VERSION "(null)"

NS_ :

BS_:

BU_:
VAL_TABLE_ Img 6 "Description for the value '0x6'" 5 "Description for the value '0x5'" 4 "Description for the value '0x4'" 3 "Description for the value '0x3'" 2 "Bertone" 1 "GB110" 0 "Car Parameter" ;

BO_ 16 Schermata: 1 Vector__XXX
 SG_ Setup : 0|8@1+ (1,0) [0|255] "" Vector__XXX

BO_ 290 battery: 2 Vector__XXX
 SG_ voltage : 8|8@1+ (1,0) [0|255] "" Vector__XXX
 SG_ temperature : 0|8@1+ (1,0) [0|255] "" Vector__XXX

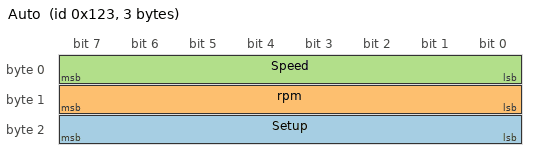
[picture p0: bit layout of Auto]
BO_ 291 Auto: 3 Vector__XXX
 SG_ Setup : 16|8@1+ (1,0) [0|255] "" Vector__XXX
 SG_ rpm : 8|8@1+ (1,0) [0|255] "" Vector__XXX
 SG_ Speed : 0|8@1+ (1,0) [0|255] "khm" Vector__XXX

BA_DEF_  "BusType" STRING ;
BA_DEF_ EV_  "Novi, Michigan, USA_Lon" FLOAT -180 180;
BA_DEF_ EV_  "Novi, Michigan, USA_Lat" FLOAT -90 90;
BA_DEF_ EV_  "Tokio, Japan_Lon" FLOAT -180 180;
BA_DEF_ EV_  "Tokio, Japan_Lat" FLOAT -90 90;
BA_DEF_ EV_  "Stuttgart, Germany_Alt" FLOAT 0 0;
BA_DEF_ EV_  "Stuttgart, Germany_Lon" FLOAT -180 180;
BA_DEF_ EV_  "Stuttgart, Germany_Lat" FLOAT -90 90;
BA_DEF_DEF_  "BusType" "";
BA_DEF_DEF_  "Novi, Michigan, USA_Lon" -83.29;
BA_DEF_DEF_  "Novi, Michigan, USA_Lat" 42.29;
BA_DEF_DEF_  "Tokio, Japan_Lon" 139.46;
BA_DEF_DEF_  "Tokio, Japan_Lat" 35.42;
BA_DEF_DEF_  "Stuttgart, Germany_Alt" 225;
BA_DEF_DEF_  "Stuttgart, Germany_Lon" 9.11;
BA_DEF_DEF_  "Stuttgart, Germany_Lat" 48.46;
BA_ "BusType" "CAN";
VAL_ 16 Setup 6 "Description for the value '0x6'" 5 "Description for the value '0x5'" 4 "Description for the value '0x4'" 3 "Description for the value '0x3'" 2 "Bertone" 1 "GB110" 0 "Car Parameter" ;
VAL_ 291 Setup 6 "Description for the value '0x6'" 5 "Description for the value '0x5'" 4 "Description for the value '0x4'" 3 "Description for the value '0x3'" 2 "Bertone" 1 "GB110" 0 "Car Parameter" ;
